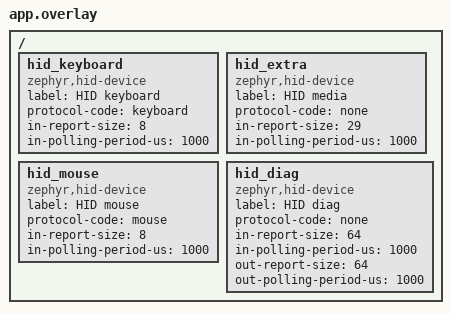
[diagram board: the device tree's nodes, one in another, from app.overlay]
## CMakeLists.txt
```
cmake_minimum_required(VERSION 3.20.0)

find_package(Zephyr REQUIRED HINTS $ENV{ZEPHYR_BASE})
project(spare_dongle)

set(manifest ${CMAKE_CURRENT_SOURCE_DIR}/tool/Cargo.toml)
set_property(DIRECTORY APPEND PROPERTY CMAKE_CONFIGURE_DEPENDS ${manifest})
file(STRINGS ${manifest} version_line REGEX "^version = \"[0-9]+\\.[0-9]+\\.[0-9]+\"$" LIMIT_COUNT 1)
if(NOT version_line MATCHES "([0-9]+)\\.([0-9]+)\\.([0-9]+)")
  message(FATAL_ERROR "no version line in ${manifest}")
endif()
set_property(SOURCE src/core.c APPEND PROPERTY COMPILE_DEFINITIONS
  FIRMWARE_VERSION_MAJOR=${CMAKE_MATCH_1} FIRMWARE_VERSION_MINOR=${CMAKE_MATCH_2}
  FIRMWARE_VERSION_PATCH=${CMAKE_MATCH_3})

target_sources(app PRIVATE
  src/main.c src/core.c src/nuphy_main.c src/unifying_main.c src/radio.c src/noise.c src/usb.c
  src/indicator.c src/nuphy.c src/unifying.c src/protocol.c src/reports.c src/chanpick.c
  src/link.c src/store.c src/diag.c src/history.c src/pairwin.c src/chanwatch.c
  src/ble.c src/bluetooth_main.c src/hidmap.c src/hidkeys.c src/hidpp.c
  src/btpolicy.c src/btlist.c src/bootinfo.c)

include(ffi/diagwire.cmake)
# CONFIG_FPU is off, so the firmware uses the soft-float ABI.
diagwire_build(thumbv7em-none-eabi)
target_link_libraries(app PRIVATE diagwire)
```

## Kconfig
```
mainmenu "spare-dongle"

config COUNTERS
	bool "Print link and USB counters on the console every 10 s"
	default y

source "Kconfig.zephyr"
```

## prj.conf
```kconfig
CONFIG_SERIAL=y
CONFIG_CONSOLE=y
CONFIG_UART_CONSOLE=y
CONFIG_UART_LINE_CTRL=y
CONFIG_PRINTK=y
CONFIG_USB_DEVICE_STACK_NEXT=y
CONFIG_CDC_ACM_SERIAL_INITIALIZE_AT_BOOT=n
CONFIG_USBD_CDC_ACM_CLASS=y
CONFIG_USBD_HID_SUPPORT=y
CONFIG_HWINFO=y
CONFIG_REBOOT=y
CONFIG_MAIN_STACK_SIZE=2048
CONFIG_ESB=y
CONFIG_CLOCK_CONTROL=y
CONFIG_ESB_CLOCK_INIT=y
CONFIG_FLASH=y
CONFIG_FLASH_MAP=y
CONFIG_NVS=y
CONFIG_SETTINGS=y
CONFIG_SETTINGS_NVS=y
CONFIG_WATCHDOG=y
CONFIG_ENTROPY_GENERATOR=y
CONFIG_ESB_DYNAMIC_INTERRUPTS=y
CONFIG_MPSL_DYNAMIC_INTERRUPTS=y
CONFIG_BT=y
CONFIG_BT_CENTRAL=y
CONFIG_BT_SMP=y
CONFIG_BT_SETTINGS=y
CONFIG_BT_GATT_CLIENT=y
CONFIG_BT_GATT_DM=y
CONFIG_BT_HOGP=y
CONFIG_BT_MAX_CONN=2
CONFIG_BT_MAX_PAIRED=8
CONFIG_BT_DEVICE_NAME="SpareDongle"
CONFIG_HEAP_MEM_POOL_SIZE=2048
CONFIG_SYSTEM_WORKQUEUE_STACK_SIZE=2048
CONFIG_BT_HOGP_REPORTS_MAX=16
CONFIG_BT_GATT_DM_MAX_ATTRS=80
CONFIG_BT_SMP_SC_PAIR_ONLY=n
CONFIG_BT_ATT_TX_COUNT=17
CONFIG_BT_BAS_CLIENT=y
CONFIG_BT_SCAN_WITH_IDENTITY=y
CONFIG_BT_APP_PASSKEY=y
CONFIG_BT_CTLR_CONN_RSSI=y
CONFIG_BT_HCI_VS_EVT_USER=y
CONFIG_BT_CTLR_SDC_QOS_CHANNEL_SURVEY=y
```

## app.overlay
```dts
/ {
	hid_keyboard: hid_keyboard {
		compatible = "zephyr,hid-device";
		label = "HID keyboard";
		protocol-code = "keyboard";
		in-report-size = <8>;
		in-polling-period-us = <1000>;
	};

	hid_extra: hid_extra {
		compatible = "zephyr,hid-device";
		label = "HID media";
		protocol-code = "none";
		in-report-size = <29>;
		in-polling-period-us = <1000>;
	};

	hid_mouse: hid_mouse {
		compatible = "zephyr,hid-device";
		label = "HID mouse";
		protocol-code = "mouse";
		in-report-size = <8>;
		in-polling-period-us = <1000>;
	};

	hid_diag: hid_diag {
		compatible = "zephyr,hid-device";
		label = "HID diag";
		protocol-code = "none";
		in-report-size = <64>;
		in-polling-period-us = <1000>;
		out-report-size = <64>;
		out-polling-period-us = <1000>;
	};
};
```

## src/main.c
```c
#include <hal/nrf_timer.h>
#include <zephyr/drivers/hwinfo.h>
#include <zephyr/init.h>
#include <zephyr/sys/printk.h>
#include "bootinfo.h"
#include "core.h"
#include "store.h"

/* The SoftDevice sits above the 4 kB MBR and keeps its information structure 0x2000 into itself. */
#define SD_INFO_ADDRESS 0x3000

static uint32_t bootloader_version_register;

/* TIMER2's CC[0] holds the bootloader's version only until a driver or radio stack reuses the
 * timer, and PRE_KERNEL_1 runs before any of them start. */
static int capture_bootloader_version(void)
{
	bootloader_version_register = nrf_timer_cc_get(NRF_TIMER2, NRF_TIMER_CC_CHANNEL0);
	return 0;
}

SYS_INIT(capture_bootloader_version, PRE_KERNEL_1, 0);

int main(void)
{
	uint32_t reset_cause = 0;
	uint8_t stored = 0;
	bool loaded = false;
	enum protocol active;
	struct bootinfo boot;
	int store_err;

	hwinfo_get_reset_cause(&reset_cause);
	hwinfo_clear_reset_cause();
	bootinfo_read(&boot, reset_cause, bootloader_version_register,
		      (const uint8_t *)SD_INFO_ADDRESS);
	store_err = store_init();
	if (store_err) {
		printk("store init failed: %d\n", store_err);
	} else {
		loaded = store_load_protocol(&stored);
	}
	active = protocol_from_stored(loaded, stored);
	core_start(active, &boot);
	if (active == PROTOCOL_BLUETOOTH) {
		bluetooth_run(store_err);
	}
	if (active == PROTOCOL_UNIFYING) {
		unifying_run(store_err);
	}
	nuphy_run(store_err);
	return 0;
}
```

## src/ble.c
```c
#include <string.h>
#include <zephyr/bluetooth/bluetooth.h>
#include <zephyr/bluetooth/conn.h>
#include <zephyr/bluetooth/gatt.h>
#include <zephyr/bluetooth/hci.h>
#include <zephyr/bluetooth/uuid.h>
#include <zephyr/kernel.h>
#include <zephyr/settings/settings.h>
#include <zephyr/sys/byteorder.h>
#include <zephyr/sys/printk.h>
#include <bluetooth/gatt_dm.h>
#include <bluetooth/hci_vs_sdc.h>
#include <bluetooth/services/bas_client.h>
#include <bluetooth/services/hogp.h>
/* Host-internal: the public API gives a bond's address but not how it paired. */
#include <host/keys.h>
#include "ble.h"
#include "clock.h"
#include "core.h"

K_MSGQ_DEFINE(ble_events, sizeof(struct ble_event), 16, 4);

BUILD_ASSERT(CONFIG_BT_MAX_CONN == DEVICE_KINDS);
BUILD_ASSERT(CONFIG_BT_MAX_PAIRED == BTPOLICY_STORED_MAX);
BUILD_ASSERT(BTPOLICY_APPEARANCE_KEYBOARD == BT_APPEARANCE_HID_KEYBOARD);
BUILD_ASSERT(BTPOLICY_APPEARANCE_MOUSE == BT_APPEARANCE_HID_MOUSE);

/* In the order waiting discoveries start. */
enum discovery {
	DISCOVERY_NONE,
	DISCOVERY_HID,
	DISCOVERY_BATTERY,
};

struct link {
	struct bt_conn *conn;
	struct bt_hogp hogp;
	struct bt_bas_client bas;
	uint8_t map[BLE_MAP_MAX];
	size_t map_len;
	char name[BLE_NAME_MAX + 1];
	struct bt_gatt_read_params name_read;
	enum discovery wanted;
	bool failed;
	bool passkey_used;
};

static struct link links[DEVICE_KINDS];
/* A new device's advert that lacked the HID service or a kind, kept for its scan response. */
static struct btpolicy_advert pending;
static bool pending_set;
static enum btpolicy_scan scan_mode;
static uint32_t passkey;
static bool offering;

static enum device_kind kind_of(const struct link *l)
{
	return (enum device_kind)(l - links);
}

static struct link *link_of_conn(const struct bt_conn *conn)
{
	for (int k = 0; k < DEVICE_KINDS; k++) {
		if (links[k].conn == conn) {
			return &links[k];
		}
	}
	return NULL;
}

static void put_event(const struct ble_event *ev)
{
	if (k_msgq_put(&ble_events, ev, K_NO_WAIT) != 0) {
		core_count_dropped();
		printk("bluetooth event dropped\n");
	}
}

static void emit(struct link *l, struct ble_event ev)
{
	ev.kind = kind_of(l);
	put_event(&ev);
}

static enum btpolicy_failure failure_of(enum ble_stage stage, int error)
{
	if (stage != BLE_STAGE_SECURITY || error == BT_SECURITY_ERR_UNSPECIFIED) {
		return BTPOLICY_FAILURE_LINK;
	}
	return error == BT_SECURITY_ERR_PIN_OR_KEY_MISSING ? BTPOLICY_FAILURE_KEY_MISSING
							   : BTPOLICY_FAILURE_REFUSAL;
}

static void emit_failed(struct link *l, enum ble_stage stage, int error)
{
	emit(l, (struct ble_event){
			.type = BLE_FAILED,
			.failed = {.stage = stage, .error = error, .why = failure_of(stage, error)},
		});
}

static void fail(struct link *l, enum ble_stage stage, int error)
{
	/* The stages still running when one fails, or when the connection is being closed, end in
	 * errors of their own. */
	if (l->failed) {
		return;
	}
	l->failed = true;
	emit_failed(l, stage, error);
	ble_disconnect(kind_of(l));
}

static void next_discovery(void);

static void want_discovery(struct link *l, enum discovery what)
{
	l->wanted = what;
	next_discovery();
}

static uint8_t on_report(struct bt_hogp *h, struct bt_hogp_rep_info *rep, uint8_t err,
			 const uint8_t *data)
{
	struct ble_event ev = {
		.type = BLE_REPORT,
		.report = {.received_us = clock_now_us(), .id = bt_hogp_rep_id(rep)},
	};
	size_t len = bt_hogp_rep_size(rep);

	if (err || !data) {
		return BT_GATT_ITER_STOP;
	}
	ev.report.len = MIN(len, sizeof(ev.report.data));
	memcpy(ev.report.data, data, ev.report.len);
	emit(CONTAINER_OF(h, struct link, hogp), ev);
	return BT_GATT_ITER_CONTINUE;
}

/* Each subscription holds an ATT buffer until the device answers, and all are sent at once, with
 * the battery discovery's first request behind them. */
BUILD_ASSERT(CONFIG_BT_ATT_TX_COUNT >= CONFIG_BT_HOGP_REPORTS_MAX + 1);

static void subscribe(struct link *l)
{
	struct bt_hogp_rep_info *rep = NULL;

	while ((rep = bt_hogp_rep_next(&l->hogp, rep)) != NULL) {
		int err;

		if (bt_hogp_rep_type(rep) != BT_HIDS_REPORT_TYPE_INPUT) {
			continue;
		}
		err = bt_hogp_rep_subscribe(&l->hogp, rep, on_report);
		if (err) {
			fail(l, BLE_STAGE_SUBSCRIBE, err);
			return;
		}
	}
	want_discovery(l, DISCOVERY_BATTERY);
}

static void on_map_part(struct bt_hogp *h, uint8_t err, const uint8_t *data, size_t size,
			size_t offset)
{
	struct link *l = CONTAINER_OF(h, struct link, hogp);
	int ret;

	if (err) {
		fail(l, BLE_STAGE_MAP, err);
		return;
	}
	if (!data || size == 0) {
		l->map_len = offset;
		emit(l, (struct ble_event){.type = BLE_MAP_READ});
		subscribe(l);
		return;
	}
	if (offset + size > sizeof(l->map)) {
		fail(l, BLE_STAGE_MAP, -ENOMEM);
		return;
	}
	memcpy(&l->map[offset], data, size);
	ret = bt_hogp_map_read(h, on_map_part, offset + size, K_NO_WAIT);
	if (ret) {
		fail(l, BLE_STAGE_MAP, ret);
	}
}

static void on_hogp_ready(struct bt_hogp *h)
{
	int err = bt_hogp_map_read(h, on_map_part, 0, K_NO_WAIT);

	if (err) {
		fail(CONTAINER_OF(h, struct link, hogp), BLE_STAGE_MAP, err);
	}
}

static void on_hogp_failed(struct bt_hogp *h, int err)
{
	fail(CONTAINER_OF(h, struct link, hogp), BLE_STAGE_HID_SETUP, err);
}

static const struct bt_hogp_init_params hogp_params = {
	.ready_cb = on_hogp_ready,
	.prep_error_cb = on_hogp_failed,
};

/* bt_gatt_dm can end a discovery after its connection closed. */
static struct link *discovering;

/* Must run before next_discovery, which overwrites discovering. */
static struct link *take_discovering(void)
{
	struct link *l = discovering;

	discovering = NULL;
	return l;
}

static void on_discovered(struct bt_gatt_dm *dm, void *context)
{
	struct link *l = take_discovering();
	int err;

	ARG_UNUSED(context);
	if (!l) {
		bt_gatt_dm_data_release(dm);
		next_discovery();
		return;
	}
	err = bt_hogp_handles_assign(dm, &l->hogp);
	bt_gatt_dm_data_release(dm);
	next_discovery();
	if (err) {
		fail(l, BLE_STAGE_HID_SETUP, err);
	}
}

static void on_discovery_error(struct bt_conn *conn, int err, void *context)
{
	struct link *l = take_discovering();

	ARG_UNUSED(conn);
	ARG_UNUSED(context);
	next_discovery();
	if (l) {
		fail(l, BLE_STAGE_DISCOVERY, err);
	}
}

static void on_no_hid_service(struct bt_conn *conn, void *context)
{
	on_discovery_error(conn, -ENOENT, context);
}

static const struct bt_gatt_dm_cb hid_discovery = {
	.completed = on_discovered,
	.service_not_found = on_no_hid_service,
	.error_found = on_discovery_error,
};

static void emit_battery(struct bt_bas_client *bas, uint8_t level)
{
	struct device_battery b = DEVICE_BATTERY_UNKNOWN;

	if (level != BT_BAS_VAL_INVALID) {
		b.level = level;
	}
	emit(CONTAINER_OF(bas, struct link, bas),
	     (struct ble_event){.type = BLE_BATTERY, .battery = b});
}

static void on_battery_read(struct bt_bas_client *bas, uint8_t level, int err)
{
	emit_battery(bas, err ? BT_BAS_VAL_INVALID : level);
}

static void use_battery(struct link *l, struct bt_gatt_dm *dm)
{
	int err = bt_bas_handles_assign(dm, &l->bas);

	if (!err) {
		err = bt_bas_read_battery_level(&l->bas, on_battery_read);
	}
	if (!err && bt_bas_notify_supported(&l->bas)) {
		err = bt_bas_subscribe_battery_level(&l->bas, emit_battery);
	}
	if (err) {
		printk("bluetooth %s battery unread: %d\n", device_kind_name(kind_of(l)), err);
	}
}

static void on_battery_found(struct bt_gatt_dm *dm, void *context)
{
	struct link *l = take_discovering();

	ARG_UNUSED(context);
	if (l) {
		use_battery(l, dm);
	}
	bt_gatt_dm_data_release(dm);
	next_discovery();
}

static void on_no_battery(struct bt_conn *conn, void *context)
{
	ARG_UNUSED(conn);
	ARG_UNUSED(context);
	take_discovering();
	next_discovery();
}

static void on_battery_error(struct bt_conn *conn, int err, void *context)
{
	struct link *l = take_discovering();

	ARG_UNUSED(conn);
	ARG_UNUSED(context);
	if (l) {
		printk("bluetooth %s battery discovery failed: %d\n",
		       device_kind_name(kind_of(l)), err);
	}
	next_discovery();
}

static const struct bt_gatt_dm_cb battery_discovery = {
	.completed = on_battery_found,
	.service_not_found = on_no_battery,
	.error_found = on_battery_error,
};

static int start_discovery(struct link *l, enum discovery what)
{
	int err = what == DISCOVERY_HID
			  ? bt_gatt_dm_start(l->conn, BT_UUID_HIDS, &hid_discovery, NULL)
			  : bt_gatt_dm_start(l->conn, BT_UUID_BAS, &battery_discovery, NULL);

	if (!err) {
		discovering = l;
	}
	return err;
}

/* bt_gatt_dm runs one discovery at a time and refuses a second start with -EALREADY. */
static void next_discovery(void)
{
	for (;;) {
		struct link *l = NULL;
		enum discovery what;
		int err;

		for (int k = 0; k < DEVICE_KINDS; k++) {
			if (links[k].wanted != DISCOVERY_NONE &&
			    (!l || links[k].wanted < l->wanted)) {
				l = &links[k];
			}
		}
		if (!l) {
			return;
		}
		what = l->wanted;
		err = start_discovery(l, what);
		if (err == -EALREADY) {
			return;
		}
		l->wanted = DISCOVERY_NONE;
		if (!err) {
			return;
		}
		if (what == DISCOVERY_HID) {
			fail(l, BLE_STAGE_DISCOVERY, err);
		} else {
			printk("bluetooth %s battery discovery not started: %d\n",
			       device_kind_name(kind_of(l)), err);
		}
	}
}

static void copy_name(char out[BLE_NAME_MAX + 1], const void *data, size_t len)
{
	len = MIN(len, BLE_NAME_MAX);
	memcpy(out, data, len);
	out[len] = '\0';
}

static uint8_t on_name(struct bt_conn *conn, uint8_t err, struct bt_gatt_read_params *params,
		       const void *data, uint16_t length)
{
	struct link *l = CONTAINER_OF(params, struct link, name_read);

	ARG_UNUSED(conn);
	if (!err && data) {
		copy_name(l->name, data, length);
	}
	want_discovery(l, DISCOVERY_HID);
	return BT_GATT_ITER_STOP;
}

static void read_name(struct link *l)
{
	l->name_read = (struct bt_gatt_read_params){
		.func = on_name,
		.by_uuid = {
			.start_handle = BT_ATT_FIRST_ATTRIBUTE_HANDLE,
			.end_handle = BT_ATT_LAST_ATTRIBUTE_HANDLE,
			.uuid = BT_UUID_GAP_DEVICE_NAME,
		},
	};
	if (bt_gatt_read(l->conn, &l->name_read) != 0) {
		want_discovery(l, DISCOVERY_HID);
	}
}

BUILD_ASSERT(BLE_ADDRESS_MAX >= BT_ADDR_LE_STR_LEN);
BUILD_ASSERT(BLE_REASON_NOT_ESTABLISHED == BT_HCI_ERR_CONN_FAIL_TO_ESTAB);
BUILD_ASSERT(sizeof(bt_addr_le_t) == BTPOLICY_ADDR_LEN);

static void connection_ended(struct link *l, uint8_t reason)
{
	if (bt_hogp_assign_check(&l->hogp)) {
		bt_hogp_release(&l->hogp);
	}
	l->wanted = DISCOVERY_NONE;
	if (discovering == l) {
		discovering = NULL;
	}
	bt_conn_unref(l->conn);
	l->conn = NULL;
	emit(l, (struct ble_event){.type = BLE_DISCONNECTED, .reason = reason});
}

static void print_params(struct link *l)
{
	struct bt_conn_info info;

	if (bt_conn_get_info(l->conn, &info) == 0) {
		printk("bluetooth %s link: interval %u us, latency %u, timeout %u ms\n",
		       device_kind_name(kind_of(l)), info.le.interval_us,
		       info.le.latency, info.le.timeout * 10u);
	}
}

static void on_connected(struct bt_conn *conn, uint8_t err)
{
	struct link *l = link_of_conn(conn);
	struct ble_event ev = {.type = BLE_CONNECTED};
	int ret;

	if (!l) {
		return;
	}
	if (err) {
		emit_failed(l, BLE_STAGE_CONNECT, err);
		connection_ended(l, err);
		return;
	}
	l->map_len = 0;
	bt_addr_le_to_str(bt_conn_get_dst(conn), ev.address, sizeof(ev.address));
	emit(l, ev);
	print_params(l);
	l->passkey_used = false;
	l->failed = false;
	ret = bt_conn_set_security(conn, BT_SECURITY_L2);
	if (ret) {
		fail(l, BLE_STAGE_SECURITY, ret);
	}
}

static void on_disconnected(struct bt_conn *conn, uint8_t reason)
{
	struct link *l = link_of_conn(conn);

	if (l) {
		connection_ended(l, reason);
	}
}

static void on_security_changed(struct bt_conn *conn, bt_security_t level,
				enum bt_security_err err)
{
	struct link *l = link_of_conn(conn);

	ARG_UNUSED(level);
	if (!l) {
		return;
	}
	if (err) {
		fail(l, BLE_STAGE_SECURITY, err);
		return;
	}
	read_name(l);
}

static void on_params_updated(struct bt_conn *conn, uint16_t interval, uint16_t latency,
			      uint16_t timeout)
{
	struct link *l = link_of_conn(conn);

	ARG_UNUSED(interval);
	ARG_UNUSED(latency);
	ARG_UNUSED(timeout);
	if (l) {
		print_params(l);
	}
}

BT_CONN_CB_DEFINE(conn_callbacks) = {
	.connected = on_connected,
	.disconnected = on_disconnected,
	.security_changed = on_security_changed,
	.le_param_updated = on_params_updated,
};

static void on_pairing_complete(struct bt_conn *conn, bool bonded)
{
	struct link *l = link_of_conn(conn);

	if (l && bonded) {
		emit(l, (struct ble_event){.type = BLE_PAIRED, .passkey_used = l->passkey_used});
	}
}

static struct bt_conn_auth_info_cb pairing_callbacks = {
	.pairing_complete = on_pairing_complete,
};

static bool parse_field(struct bt_data *data, void *user_data)
{
	struct btpolicy_advert *a = user_data;

	if (data->type == BT_DATA_NAME_COMPLETE || data->type == BT_DATA_NAME_SHORTENED) {
		copy_name(a->name, data->data, data->data_len);
	}

	if (data->type == BT_DATA_GAP_APPEARANCE && data->data_len == 2 &&
	    a->kind == DEVICE_NO_KIND) {
		a->kind = btpolicy_kind_of(sys_get_le16(data->data));
	}
	if (data->type != BT_DATA_UUID16_SOME && data->type != BT_DATA_UUID16_ALL) {
		return true;
	}
	for (size_t i = 0; i + 1 < data->data_len; i += 2) {
		if (sys_get_le16(&data->data[i]) == BT_UUID_HIDS_VAL) {
			a->hid_service = true;
		}
	}
	return true;
}

static void on_advert(const bt_addr_le_t *addr, int8_t rssi, uint8_t type,
		      struct net_buf_simple *data)
{
	struct ble_event ev = {.type = BLE_ADVERT};
	struct btpolicy_advert *a = &ev.advert;
	bool response = type == BT_GAP_ADV_TYPE_SCAN_RSP;

	ARG_UNUSED(rssi);
	if (response) {
		if (!pending_set || memcmp(pending.addr, addr, sizeof(pending.addr)) != 0) {
			return;
		}
		*a = pending;
		pending_set = false;
	} else {
		a->directed = type == BT_GAP_ADV_TYPE_ADV_DIRECT_IND;
		a->connectable = a->directed || type == BT_GAP_ADV_TYPE_ADV_IND;
		a->stored = bt_le_bond_exists(BT_ID_DEFAULT, addr);
		a->kind = DEVICE_NO_KIND;
		memcpy(a->addr, addr, sizeof(a->addr));
	}
	if (!a->directed) {
		bt_data_parse(data, parse_field, a);
	}
	/* Adverts from other devices would fill the event queue. */
	if (!btpolicy_interesting(a)) {
		if (!response && scan_mode == BTPOLICY_SCAN_ACTIVE && a->connectable &&
		    !a->directed) {
			pending = *a;
			pending_set = true;
		}
		return;
	}
	put_event(&ev);
}

int ble_scan(enum btpolicy_scan mode)
{
	bool pairing;
	int err;

	if (mode == scan_mode) {
		return 0;
	}
	if (scan_mode != BTPOLICY_SCAN_OFF) {
		err = bt_le_scan_stop();
		if (err) {
			return err;
		}
		scan_mode = BTPOLICY_SCAN_OFF;
	}
	if (mode == BTPOLICY_SCAN_OFF) {
		return 0;
	}
	pending_set = false;
	pairing = mode == BTPOLICY_SCAN_ACTIVE;
	/* The fast scan window takes radio time from a connected mouse, about an eighth of its
	 * reports. */
	err = bt_le_scan_start(
		BT_LE_SCAN_PARAM(pairing ? BT_LE_SCAN_TYPE_ACTIVE : BT_LE_SCAN_TYPE_PASSIVE,
				 BT_LE_SCAN_OPT_NONE,
				 pairing ? BT_GAP_SCAN_FAST_INTERVAL : BT_GAP_SCAN_SLOW_INTERVAL_1,
				 pairing ? BT_GAP_SCAN_FAST_WINDOW : BT_GAP_SCAN_SLOW_WINDOW_1),
		on_advert);
	if (!err) {
		scan_mode = mode;
	}
	return err;
}

/* Reading a device's services takes dozens of exchanges, each two connection intervals long. */
#define SHORTEST_INTERVAL 6 /* 7.5 ms */
#define SETUP_CONN_PARAM                                                                           \
	BT_LE_CONN_PARAM(SHORTEST_INTERVAL, SHORTEST_INTERVAL, 0, BT_GAP_MS_TO_CONN_TIMEOUT(4000))

int ble_connect(enum device_kind kind, const uint8_t addr[BTPOLICY_ADDR_LEN],
		const char *advertised_name)
{
	struct link *l = &links[kind];
	bt_addr_le_t peer;
	int err;

	if (l->conn) {
		return -EALREADY;
	}
	copy_name(l->name, advertised_name, strlen(advertised_name));
	memcpy(&peer, addr, sizeof(peer));
	err = bt_conn_le_create(&peer, BT_CONN_LE_CREATE_CONN, SETUP_CONN_PARAM, &l->conn);
	if (err) {
		l->conn = NULL;
	}
	return err;
}

/* Each passkey serves one pairing, since a failed or abandoned attempt can reveal it. */
static uint32_t on_app_passkey(struct bt_conn *conn)
{
	struct link *l = link_of_conn(conn);
	uint32_t offered = passkey;

	if (l) {
		l->passkey_used = true;
		emit(l, (struct ble_event){.type = BLE_PASSKEY_AWAITED, .passkey = offered});
	}
	passkey = BT_PASSKEY_RAND;
	return offered;
}

static void on_pairing_cancel(struct bt_conn *conn)
{
	ARG_UNUSED(conn);
}

static const struct bt_conn_auth_cb passkey_callbacks = {
	.app_passkey = on_app_passkey,
	.cancel = on_pairing_cancel,
};

int ble_offer_passkey(bool on, uint32_t value)
{
	int err;

	passkey = value;
	if (on == offering) {
		return 0;
	}
	err = bt_conn_auth_cb_register(on ? &passkey_callbacks : NULL);
	if (!err) {
		offering = on;
	}
	return err;
}

struct bonds {
	uint8_t (*addrs)[BTPOLICY_ADDR_LEN];
	uint8_t cap;
	uint8_t count;
};

static void add_bond(const struct bt_bond_info *info, void *user_data)
{
	struct bonds *bonds = user_data;

	if (bonds->count < bonds->cap) {
		memcpy(bonds->addrs[bonds->count], &info->addr, BTPOLICY_ADDR_LEN);
	}
	bonds->count++;
}

uint8_t ble_stored(uint8_t addrs[][BTPOLICY_ADDR_LEN], uint8_t cap)
{
	struct bonds bonds = {.addrs = addrs, .cap = cap};

	bt_foreach_bond(BT_ID_DEFAULT, add_bond, &bonds);
	return bonds.count;
}

uint8_t ble_stored_count(void)
{
	return ble_stored(NULL, 0);
}

int ble_forget(const uint8_t addr[BTPOLICY_ADDR_LEN])
{
	bt_addr_le_t peer;

	memcpy(&peer, addr, sizeof(peer));
	return bt_unpair(BT_ID_DEFAULT, &peer);
}

/* The advertising channels hold the indexes above these, and nearby devices advertise there all the
 * time. */
#define DATA_CHANNELS 37
#define ENERGY_NOT_MEASURED 127
#define SURVEY_INTERVAL_US 10000

/* The host's receive thread adds to the tally while the main loop takes it. */
static struct noise_tally data_noise;

static bool on_vendor_event(struct net_buf_simple *buf)
{
	const sdc_hci_subevent_vs_qos_channel_survey_report_t *r;

	if (net_buf_simple_pull_u8(buf) != SDC_HCI_SUBEVENT_VS_QOS_CHANNEL_SURVEY_REPORT ||
	    buf->len < sizeof(*r)) {
		return false;
	}
	r = (const void *)buf->data;
	k_sched_lock();
	for (int ch = 0; ch < DATA_CHANNELS; ch++) {
		if (r->channel_energy[ch] != ENERGY_NOT_MEASURED) {
			noise_add(&data_noise, r->channel_energy[ch]);
		}
	}
	k_sched_unlock();
	return true;
}

static int start_survey(void)
{
	sdc_hci_cmd_vs_qos_channel_survey_enable_t survey = {
		.enable = 1,
		.interval_us = SURVEY_INTERVAL_US,
	};
	int err = bt_hci_register_vnd_evt_cb(on_vendor_event);

	return err ? err : hci_vs_sdc_qos_channel_survey_enable(&survey);
}

bool ble_take_noise(struct noise_tally *t, int *home)
{
	k_sched_lock();
	*t = data_noise;
	data_noise = (struct noise_tally){0};
	k_sched_unlock();
	*home = CHANMOVE_NO_HOME;
	return true;
}

int ble_start(void)
{
	int err = bt_enable(NULL);

	if (!err) {
		err = settings_load();
	}
	if (!err) {
		err = bt_conn_auth_info_cb_register(&pairing_callbacks);
	}
	for (int k = 0; !err && k < DEVICE_KINDS; k++) {
		bt_hogp_init(&links[k].hogp, &hogp_params);
		bt_bas_client_init(&links[k].bas);
	}
	if (!err) {
		int survey_err = start_survey();

		if (survey_err) {
			printk("bluetooth noise survey not started: %d\n", survey_err);
		}
	}
	return err;
}

bool ble_take_event(struct ble_event *ev, k_timeout_t wait)
{
	return k_msgq_get(&ble_events, ev, wait) == 0;
}

size_t ble_copy_map(enum device_kind kind, uint8_t *out, size_t cap)
{
	size_t len;

	k_sched_lock();
	len = MIN(links[kind].map_len, cap);
	memcpy(out, links[kind].map, len);
	k_sched_unlock();
	return len;
}

void ble_copy_name(enum device_kind kind, char out[BLE_NAME_MAX + 1])
{
	k_sched_lock();
	memcpy(out, links[kind].name, sizeof(links[kind].name));
	k_sched_unlock();
}

void ble_disconnect(enum device_kind kind)
{
	struct link *l = &links[kind];

	l->failed = true;
	if (l->conn) {
		bt_conn_disconnect(l->conn, BT_HCI_ERR_REMOTE_USER_TERM_CONN);
	}
}

static void on_written(struct bt_hogp *h, struct bt_hogp_rep_info *rep, uint8_t err)
{
	ARG_UNUSED(h);
	ARG_UNUSED(rep);
	ARG_UNUSED(err);
}

int ble_write_report(enum device_kind kind, uint8_t report_id, const uint8_t *data, uint8_t len)
{
	struct bt_hogp *hogp = &links[kind].hogp;
	struct bt_hogp_rep_info *rep;

	if (!bt_hogp_ready_check(hogp)) {
		return -ENOTCONN;
	}
	rep = bt_hogp_rep_find(hogp, BT_HIDS_REPORT_TYPE_OUTPUT, report_id);
	if (!rep) {
		return -ENOENT;
	}
	/* The library refuses a write without a completion callback. */
	return bt_hogp_rep_write_wo_rsp(hogp, rep, data, len, on_written);
}

bool ble_bond_secure(const uint8_t addr[BTPOLICY_ADDR_LEN])
{
	bt_addr_le_t peer;
	const struct bt_keys *keys;

	memcpy(&peer, addr, sizeof(peer));
	keys = bt_keys_find_addr(BT_ID_DEFAULT, &peer);
	return keys && (keys->flags & BT_KEYS_SC);
}

int ble_rssi(enum device_kind kind, int8_t *dbm)
{
	struct bt_conn *conn = links[kind].conn;
	struct bt_hci_cp_read_rssi *cp;
	struct net_buf *buf;
	struct net_buf *rsp;
	uint16_t handle;
	int8_t rssi;
	int err;

	if (!conn || bt_hci_get_conn_handle(conn, &handle)) {
		return -ENOTCONN;
	}
	buf = bt_hci_cmd_alloc(K_MSEC(10));
	if (!buf) {
		return -ENOBUFS;
	}
	cp = net_buf_add(buf, sizeof(*cp));
	cp->handle = sys_cpu_to_le16(handle);
	err = bt_hci_cmd_send_sync(BT_HCI_OP_READ_RSSI, buf, &rsp);
	if (err) {
		return err;
	}
	rssi = ((struct bt_hci_rp_read_rssi *)rsp->data)->rssi;
	net_buf_unref(rsp);
	if (rssi == BT_HCI_LE_RSSI_NOT_AVAILABLE) {
		return -ENODATA;
	}
	*dbm = rssi;
	return 0;
}

const char *ble_stage_name(enum ble_stage stage)
{
	switch (stage) {
	case BLE_STAGE_CONNECT:
		return "connect";
	case BLE_STAGE_SECURITY:
		return "security";
	case BLE_STAGE_DISCOVERY:
		return "discovery";
	case BLE_STAGE_HID_SETUP:
		return "hid setup";
	case BLE_STAGE_MAP:
		return "report map";
	case BLE_STAGE_SUBSCRIBE:
		return "subscribe";
	}
	return "unknown";
}
```

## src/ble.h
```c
#ifndef BLE_H
#define BLE_H

#include <stdbool.h>
#include <stddef.h>
#include <stdint.h>

#include <zephyr/kernel.h>

#include "btpolicy.h"
#include "noise.h"

#define BLE_REPORT_MAX 64
#define BLE_MAP_MAX 1024
#define BLE_NAME_MAX BTPOLICY_NAME_MAX
#define BLE_ADDRESS_MAX 30
#define BLE_REASON_NOT_ESTABLISHED 0x3e

enum ble_event_type {
	BLE_ADVERT,
	BLE_CONNECTED,
	BLE_DISCONNECTED,
	BLE_FAILED,
	BLE_PAIRED,
	/* The device waits for the offered passkey to be typed on it. */
	BLE_PASSKEY_AWAITED,
	BLE_MAP_READ,
	BLE_REPORT,
	BLE_BATTERY,
};

enum ble_stage {
	BLE_STAGE_CONNECT,
	BLE_STAGE_SECURITY,
	BLE_STAGE_DISCOVERY,
	BLE_STAGE_HID_SETUP,
	BLE_STAGE_MAP,
	BLE_STAGE_SUBSCRIBE,
};

struct ble_event {
	enum ble_event_type type;
	/* The slot the event is about; unset for BLE_ADVERT. */
	enum device_kind kind;
	union {
		/* BLE_ADVERT: from a stored device or one offering the HID service. */
		struct btpolicy_advert advert;
		/* BLE_CONNECTED: the device's address as text. */
		char address[BLE_ADDRESS_MAX];
		/* BLE_DISCONNECTED: the stack's reason code, BLE_REASON_NOT_ESTABLISHED when the
		 * device never joined the connection. */
		uint8_t reason;
		/* BLE_FAILED */
		struct {
			enum ble_stage stage;
			int error;
			enum btpolicy_failure why;
		} failed;
		/* BLE_PAIRED: the device was typed the offered passkey. */
		bool passkey_used;
		/* BLE_PASSKEY_AWAITED: the passkey the device was given. */
		uint32_t passkey;
		/* BLE_REPORT: the bytes exclude the report ID. */
		struct {
			uint32_t received_us;
			uint8_t id;
			uint8_t len;
			uint8_t data[BLE_REPORT_MAX];
		} report;
		/* BLE_BATTERY: the level is unknown once it cannot be read. */
		struct device_battery battery;
	};
};

/* Starts the Bluetooth stack; a second call fails with -EALREADY once the first has run. */
int ble_start(void);
/* Does nothing when scanning is already in the mode asked for; an active scan asks every
 * advertiser for its scan response. */
int ble_scan(enum btpolicy_scan mode);
/* Every call that returns 0 ends in one BLE_DISCONNECTED for the slot, after a BLE_FAILED when a
 * stage failed. */
int ble_connect(enum device_kind kind, const uint8_t addr[BTPOLICY_ADDR_LEN],
		const char *advertised_name);
/* While on, a keyboard able to take a passkey is asked for this six-digit one as it pairs. */
int ble_offer_passkey(bool on, uint32_t value);
uint8_t ble_stored_count(void);
/* Copies up to cap bonded addresses and returns how many bonds there are. */
uint8_t ble_stored(uint8_t addrs[][BTPOLICY_ADDR_LEN], uint8_t cap);
/* Deletes the device's bond, disconnecting it first if it is connected. */
int ble_forget(const uint8_t addr[BTPOLICY_ADDR_LEN]);
bool ble_take_event(struct ble_event *ev, k_timeout_t wait);
/* Copies the report map read at the slot's connection and returns its length, 0 before its
 * BLE_MAP_READ. */
size_t ble_copy_map(enum device_kind kind, uint8_t *out, size_t cap);
/* The name of the slot's device, the advertised one until its own is read; empty if it gave
 * none. */
void ble_copy_name(enum device_kind kind, char out[BLE_NAME_MAX + 1]);
void ble_disconnect(enum device_kind kind);
/* Writes the slot's output report with this ID, data excluding the ID; fails until the device's
 * reports are discovered and while an earlier write to that report is still being sent. */
int ble_write_report(enum device_kind kind, uint8_t report_id, const uint8_t *data, uint8_t len);
/* Reads the slot's signal from the controller; fails with -ENOTCONN without a device and -ENODATA
 * when the controller has no reading yet. */
int ble_rssi(enum device_kind kind, int8_t *dbm);
/* Whether the bond with the device was made by LE Secure Connections, not legacy pairing; false
 * for an address without a bond. */
bool ble_bond_secure(const uint8_t addr[BTPOLICY_ADDR_LEN]);
const char *ble_stage_name(enum ble_stage stage);
/* Takes the energy read on the data channels since the last call; it always counts toward the
 * minute, since the links hop over every data channel; *home is always CHANMOVE_NO_HOME. */
bool ble_take_noise(struct noise_tally *t, int *home);

#endif
```

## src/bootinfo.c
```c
#include <string.h>
#include "bootinfo.h"

#define SD_INFO_SIZE 0x00
#define SD_MAGIC 0x04
#define SD_FWID 0x0c
#define SD_ID 0x10
#define SD_VERSION 0x14
#define SD_MAGIC_NUMBER 0x51b1e5dbu

static uint32_t le32(const uint8_t *p)
{
	return p[0] | p[1] << 8 | p[2] << 16 | (uint32_t)p[3] << 24;
}

void bootinfo_read(struct bootinfo *out, uint32_t reset_cause, uint32_t version_register,
		   const uint8_t sd_info[BOOTINFO_SD_INFO_LEN])
{
	memset(out, 0, sizeof(*out));
	out->reset_cause = reset_cause;
	/* The bootloader packs major, minor and patch into the low three bytes. */
	if ((version_register >> 24) == 0) {
		out->bootloader[0] = version_register >> 16;
		out->bootloader[1] = version_register >> 8;
		out->bootloader[2] = version_register;
	}
	if (le32(&sd_info[SD_MAGIC]) != SD_MAGIC_NUMBER) {
		return;
	}
	out->softdevice_fwid = sd_info[SD_FWID] | sd_info[SD_FWID + 1] << 8;
	/* A field lies inside the structure only where its size byte reaches past the field's
	 * offset. */
	if (sd_info[SD_INFO_SIZE] > SD_ID) {
		out->softdevice_id = le32(&sd_info[SD_ID]);
	}
	if (sd_info[SD_INFO_SIZE] > SD_VERSION) {
		out->softdevice_version = le32(&sd_info[SD_VERSION]);
	}
}
```

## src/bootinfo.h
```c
#ifndef BOOTINFO_H
#define BOOTINFO_H

#include <stdint.h>

#include "diagwire.h"

/* The SoftDevice information structure's fields up to and including its version. */
#define BOOTINFO_SD_INFO_LEN 0x18

/* version_register is TIMER2's CC[0] as the Adafruit bootloader leaves it; sd_info is the flash at
 * the SoftDevice's information structure. */
void bootinfo_read(struct bootinfo *out, uint32_t reset_cause, uint32_t version_register,
		   const uint8_t sd_info[BOOTINFO_SD_INFO_LEN]);

#endif
```

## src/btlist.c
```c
#include <string.h>

#include "btlist.h"

#define NOT_LISTED UINT8_MAX

static uint8_t find(const struct btlist *l, const uint8_t *addr)
{
	for (uint8_t i = 0; i < l->count; i++) {
		if (memcmp(l->entries[i].addr, addr, BTPOLICY_ADDR_LEN) == 0) {
			return i;
		}
	}
	return NOT_LISTED;
}

static void remove_at(struct btlist *l, uint8_t at)
{
	memmove(&l->entries[at], &l->entries[at + 1],
		(l->count - at - 1) * sizeof(l->entries[0]));
	l->count--;
}

/* Puts the device's entry first, creating it if there is room; NULL when there is not. */
static struct btlist_entry *to_front(struct btlist *l, const uint8_t *addr, bool *changed)
{
	struct btlist_entry e = {0};
	uint8_t at = find(l, addr);

	if (at == NOT_LISTED) {
		if (l->count == BTPOLICY_STORED_MAX) {
			return NULL;
		}
		memcpy(e.addr, addr, BTPOLICY_ADDR_LEN);
		at = l->count++;
		*changed = true;
	} else {
		e = l->entries[at];
		*changed = at != 0;
	}
	memmove(&l->entries[1], &l->entries[0], at * sizeof(l->entries[0]));
	l->entries[0] = e;
	return &l->entries[0];
}

bool btlist_reconcile(struct btlist *l, const uint8_t addrs[][BTPOLICY_ADDR_LEN], size_t n)
{
	bool changed = false;

	for (uint8_t i = l->count; i-- > 0;) {
		bool bonded = false;

		for (size_t j = 0; j < n; j++) {
			bonded |= memcmp(l->entries[i].addr, addrs[j], BTPOLICY_ADDR_LEN) == 0;
		}
		if (!bonded) {
			remove_at(l, i);
			changed = true;
		}
	}
	for (size_t j = 0; j < n && l->count < BTPOLICY_STORED_MAX; j++) {
		if (find(l, addrs[j]) == NOT_LISTED) {
			l->entries[l->count] = (struct btlist_entry){0};
			memcpy(l->entries[l->count++].addr, addrs[j], BTPOLICY_ADDR_LEN);
			changed = true;
		}
	}
	return changed;
}

static bool set_name(struct btlist_entry *e, const char *name)
{
	char padded[BTLIST_NAME_LEN] = {0};

	strncpy(padded, name, sizeof(padded));
	if (memcmp(e->name, padded, sizeof(padded)) == 0) {
		return false;
	}
	memcpy(e->name, padded, sizeof(padded));
	return true;
}

bool btlist_connected(struct btlist *l, const uint8_t *addr, const char *name)
{
	bool changed = false;
	struct btlist_entry *e = to_front(l, addr, &changed);

	if (!e) {
		return false;
	}
	return set_name(e, name) || changed;
}

bool btlist_paired(struct btlist *l, const uint8_t *addr, enum device_kind kind,
		   bool no_passkey, const char *name)
{
	bool changed = false;
	struct btlist_entry *e = to_front(l, addr, &changed);

	if (!e) {
		return false;
	}
	if (e->no_passkey != no_passkey || e->kind != kind) {
		e->no_passkey = no_passkey;
		e->kind = kind;
		changed = true;
	}
	if (name[0] != '\0' && set_name(e, name)) {
		changed = true;
	}
	return changed;
}

bool btlist_remove(struct btlist *l, const uint8_t *addr)
{
	uint8_t at = find(l, addr);

	if (at == NOT_LISTED) {
		return false;
	}
	remove_at(l, at);
	return true;
}

const struct btlist_entry *btlist_entry(const struct btlist *l, const uint8_t *addr)
{
	uint8_t at = find(l, addr);

	return at == NOT_LISTED ? NULL : &l->entries[at];
}

bool btlist_has(const struct btlist *l, const uint8_t *addr)
{
	return btlist_entry(l, addr) != NULL;
}

bool btlist_has_kind(const struct btlist *l, enum device_kind kind)
{
	return btlist_latest(l, kind) != NULL;
}

const struct btlist_entry *btlist_latest(const struct btlist *l, enum device_kind kind)
{
	for (uint8_t i = 0; i < l->count; i++) {
		if (l->entries[i].kind == kind) {
			return &l->entries[i];
		}
	}
	return NULL;
}

enum device_kind btlist_kind(const struct btlist *l, const uint8_t *addr)
{
	const struct btlist_entry *e = btlist_entry(l, addr);

	return e ? e->kind : DEVICE_NO_KIND;
}

_Static_assert(BTPOLICY_ADDR_LEN == DIAG_ADDR_LEN, "a device list carries the whole address");
_Static_assert(BTPOLICY_STORED_MAX <= DIAG_STORED_MAX, "a device list carries every device");

uint8_t btlist_pairing(const struct btlist_entry *e, bool secure)
{
	return diag_pairing(secure, !e->no_passkey);
}

size_t btlist_devices(const struct btlist *l, const uint8_t *const connected[DEVICE_SLOTS],
		      bool (*secure)(const uint8_t addr[BTPOLICY_ADDR_LEN]),
		      struct diag_device out[BTPOLICY_STORED_MAX])
{
	for (uint8_t i = 0; i < l->count; i++) {
		const struct btlist_entry *e = &l->entries[i];

		out[i] = (struct diag_device){
			.kind = e->kind,
			.pairing = btlist_pairing(e, secure(e->addr)),
			.slot = DEVICE_NO_SLOT,
		};
		memcpy(out[i].addr, e->addr, sizeof(out[i].addr));
		memcpy(out[i].name, e->name, sizeof(out[i].name));
		for (uint8_t s = 0; s < DEVICE_SLOTS; s++) {
			if (connected[s] && memcmp(e->addr, connected[s], BTPOLICY_ADDR_LEN) == 0) {
				out[i].slot = s;
			}
		}
	}
	return l->count;
}
```

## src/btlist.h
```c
#ifndef BTLIST_H
#define BTLIST_H

#include <stdbool.h>
#include <stddef.h>
#include <stdint.h>

#include "btpolicy.h"
#include "device.h"

#define BTLIST_NAME_LEN DIAG_NAME_MAX

struct btlist_entry {
	uint8_t addr[BTPOLICY_ADDR_LEN];
	/* Padded with zeros; not terminated when it fills the field. */
	char name[BTLIST_NAME_LEN];
	bool no_passkey;
	/* An enum device_kind; zero, a keyboard, for an entry added by btlist_reconcile. */
	uint8_t kind;
};

/* The stored devices, the most recently connected first. */
struct btlist {
	struct btlist_entry entries[BTPOLICY_STORED_MAX];
	uint8_t count;
};

/* Each of these returns true when it changed the list. */

/* Drops the entries no bond backs and adds a nameless entry, last, for each bond without one. */
bool btlist_reconcile(struct btlist *l, const uint8_t addrs[][BTPOLICY_ADDR_LEN], size_t n);
/* Moves the device to the front and records its name. */
bool btlist_connected(struct btlist *l, const uint8_t *addr, const char *name);
/* Moves the device to the front and records its kind, its passkey mark and, unless empty, its
 * name. */
bool btlist_paired(struct btlist *l, const uint8_t *addr, enum device_kind kind,
		   bool no_passkey, const char *name);
bool btlist_remove(struct btlist *l, const uint8_t *addr);

/* NULL for an address not in the list. */
const struct btlist_entry *btlist_entry(const struct btlist *l, const uint8_t *addr);
bool btlist_has(const struct btlist *l, const uint8_t *addr);
bool btlist_has_kind(const struct btlist *l, enum device_kind kind);
/* The most recently connected entry of the kind, or NULL when none is listed. */
const struct btlist_entry *btlist_latest(const struct btlist *l, enum device_kind kind);
/* DEVICE_NO_KIND for an address not in the list. */
enum device_kind btlist_kind(const struct btlist *l, const uint8_t *addr);

/* secure tells whether the entry paired with LE Secure Connections. */
uint8_t btlist_pairing(const struct btlist_entry *e, bool secure);

/* connected[s] is the address of the device ready in slot s, or NULL; secure tells whether the
 * device at an address paired with LE Secure Connections. Returns the number of devices written. */
size_t btlist_devices(const struct btlist *l, const uint8_t *const connected[DEVICE_SLOTS],
		      bool (*secure)(const uint8_t addr[BTPOLICY_ADDR_LEN]),
		      struct diag_device out[BTPOLICY_STORED_MAX]);

#endif
```

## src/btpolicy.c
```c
#include <string.h>

#include "btpolicy.h"

enum device_kind btpolicy_kind_of(uint16_t appearance)
{
	switch (appearance) {
	case BTPOLICY_APPEARANCE_KEYBOARD:
		return DEVICE_KIND_KEYBOARD;
	case BTPOLICY_APPEARANCE_MOUSE:
		return DEVICE_KIND_MOUSE;
	default:
		return DEVICE_NO_KIND;
	}
}

void btpolicy_init(struct btpolicy *p)
{
	*p = (struct btpolicy){0};
}

static bool refused(const struct btpolicy *p, const uint8_t *addr)
{
	for (uint8_t i = 0; i < p->refused_count; i++) {
		if (memcmp(p->refused[i], addr, BTPOLICY_ADDR_LEN) == 0) {
			return true;
		}
	}
	return false;
}

static bool setting_up(const struct btpolicy *p)
{
	for (int k = 0; k < DEVICE_KINDS; k++) {
		if (p->slots[k].state == BTPOLICY_CONNECTING ||
		    p->slots[k].state == BTPOLICY_CONNECTED) {
			return true;
		}
	}
	return false;
}

bool btpolicy_interesting(const struct btpolicy_advert *a)
{
	return a->connectable && (a->stored || (a->hid_service && a->kind != DEVICE_NO_KIND));
}

enum btpolicy_want btpolicy_wants(const struct btpolicy *p, const struct btpolicy_advert *a,
				  bool window_open, uint8_t stored_count, uint32_t now_ms)
{
	const struct btpolicy_slot *s;

	if (!btpolicy_interesting(a) || a->kind == DEVICE_NO_KIND || setting_up(p)) {
		return BTPOLICY_IGNORE;
	}
	s = &p->slots[a->kind];
	if (s->dropping) {
		return BTPOLICY_IGNORE;
	}
	if (a->stored) {
		bool waited = !s->retry_pending || (int32_t)(now_ms - s->retry_at_ms) >= 0;

		return s->state == BTPOLICY_IDLE && !window_open && waited ? BTPOLICY_CONNECT
									    : BTPOLICY_IGNORE;
	}
	if (!window_open || a->directed || stored_count >= BTPOLICY_STORED_MAX ||
	    refused(p, a->addr)) {
		return BTPOLICY_IGNORE;
	}
	return s->state == BTPOLICY_IDLE ? BTPOLICY_CONNECT : BTPOLICY_REPLACE;
}

void btpolicy_connecting(struct btpolicy *p, const struct btpolicy_advert *a)
{
	struct btpolicy_slot *s = &p->slots[a->kind];

	s->state = BTPOLICY_CONNECTING;
	memcpy(s->peer, a->addr, BTPOLICY_ADDR_LEN);
	s->peer_stored = a->stored;
}

void btpolicy_dropping(struct btpolicy *p, enum device_kind kind)
{
	p->slots[kind].dropping = true;
}

void btpolicy_connected(struct btpolicy *p, enum device_kind kind)
{
	p->slots[kind].state = BTPOLICY_CONNECTED;
}

const uint8_t *btpolicy_peer(const struct btpolicy *p, enum device_kind kind)
{
	return p->slots[kind].state == BTPOLICY_IDLE ? NULL : p->slots[kind].peer;
}

static void refuse_peer(struct btpolicy *p, const uint8_t *peer)
{
	if (!refused(p, peer) && p->refused_count < BTPOLICY_STORED_MAX) {
		memcpy(p->refused[p->refused_count++], peer, BTPOLICY_ADDR_LEN);
	}
}

enum btpolicy_pairing btpolicy_paired(struct btpolicy *p, enum device_kind kind,
				      bool passkey_used)
{
	struct btpolicy_slot *s = &p->slots[kind];

	if (kind == DEVICE_KIND_KEYBOARD && p->window_open && p->passkey_demanded && !passkey_used) {
		refuse_peer(p, s->peer);
		return BTPOLICY_PAIRING_FORGOTTEN;
	}
	s->peer_stored = true;
	return BTPOLICY_PAIRING_KEPT;
}

void btpolicy_ready(struct btpolicy *p, enum device_kind kind)
{
	p->slots[kind].state = BTPOLICY_READY;
}

bool btpolicy_is_ready(const struct btpolicy *p, enum device_kind kind)
{
	return p->slots[kind].state == BTPOLICY_READY;
}

void btpolicy_disconnected(struct btpolicy *p, enum device_kind kind, uint32_t now_ms,
			   bool never_joined)
{
	struct btpolicy_slot *s = &p->slots[kind];
	bool failed = s->state != BTPOLICY_READY && s->peer_stored;
	bool quick = failed && never_joined && s->quick_retries < BTPOLICY_QUICK_RETRIES;

	s->quick_retries = quick ? s->quick_retries + 1 : 0;
	s->retry_pending = failed && !quick;
	s->retry_at_ms = now_ms + BTPOLICY_RETRY_MS;
	s->state = BTPOLICY_IDLE;
	s->dropping = false;
}

enum btpolicy_security btpolicy_security_failed(struct btpolicy *p, enum device_kind kind,
						enum btpolicy_failure why)
{
	struct btpolicy_slot *s = &p->slots[kind];

	if (s->peer_stored) {
		return why == BTPOLICY_FAILURE_KEY_MISSING ? BTPOLICY_BOND_LOST
							   : BTPOLICY_SECURITY_FAILED;
	}
	if (why != BTPOLICY_FAILURE_REFUSAL) {
		return BTPOLICY_SECURITY_FAILED;
	}
	if (refused(p, s->peer)) {
		return BTPOLICY_REFUSED_BEFORE;
	}
	refuse_peer(p, s->peer);
	return BTPOLICY_PAIRING_REFUSED;
}

void btpolicy_window(struct btpolicy *p, bool open, bool passkey_demanded)
{
	if (p->window_open && !open) {
		p->refused_count = 0;
	}
	p->window_open = open;
	p->passkey_demanded = open && passkey_demanded;
}

enum btpolicy_scan btpolicy_scan(const struct btpolicy *p)
{
	bool slot_free = false;

	if (setting_up(p)) {
		return BTPOLICY_SCAN_OFF;
	}
	if (p->window_open) {
		return BTPOLICY_SCAN_ACTIVE;
	}
	for (int k = 0; k < DEVICE_KINDS; k++) {
		slot_free |= p->slots[k].state == BTPOLICY_IDLE;
	}
	return slot_free ? BTPOLICY_SCAN_PASSIVE : BTPOLICY_SCAN_OFF;
}
```

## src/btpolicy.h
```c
#ifndef BTPOLICY_H
#define BTPOLICY_H

#include <stdbool.h>
#include <stdint.h>

#include "device.h"

#define BTPOLICY_STORED_MAX 8
#define BTPOLICY_RETRY_MS 1000
#define BTPOLICY_QUICK_RETRIES 3
/* The address type, then the six address bytes. */
#define BTPOLICY_ADDR_LEN 7
#define BTPOLICY_NAME_MAX 32
#define BTPOLICY_APPEARANCE_KEYBOARD 0x03c1
#define BTPOLICY_APPEARANCE_MOUSE 0x03c2

struct btpolicy_advert {
	uint8_t addr[BTPOLICY_ADDR_LEN];
	bool connectable;
	bool directed;
	bool hid_service;
	bool stored;
	/* From the appearance for a new device, from the stored list for a stored one. */
	enum device_kind kind;
	/* Empty unless the advert or its scan response named the device. */
	char name[BTPOLICY_NAME_MAX + 1];
};

enum btpolicy_state {
	BTPOLICY_IDLE,
	BTPOLICY_CONNECTING,
	BTPOLICY_CONNECTED,
	/* The device's report map is read and its reports are forwarded. */
	BTPOLICY_READY,
};

enum btpolicy_want {
	BTPOLICY_IGNORE,
	BTPOLICY_CONNECT,
	/* The slot's device is to be dropped first; the advert is wanted once the slot is idle. */
	BTPOLICY_REPLACE,
};

enum btpolicy_scan {
	BTPOLICY_SCAN_OFF,
	BTPOLICY_SCAN_PASSIVE,
	BTPOLICY_SCAN_ACTIVE,
};

enum btpolicy_failure {
	/* The device or the dongle turned the pairing down. */
	BTPOLICY_FAILURE_REFUSAL,
	/* The device no longer holds its side of the bond. */
	BTPOLICY_FAILURE_KEY_MISSING,
	/* The link dropped before security was settled. */
	BTPOLICY_FAILURE_LINK,
};

enum btpolicy_pairing {
	BTPOLICY_PAIRING_KEPT,
	BTPOLICY_PAIRING_FORGOTTEN,
};

enum btpolicy_security {
	BTPOLICY_PAIRING_REFUSED,
	/* The same device refused earlier in this window. */
	BTPOLICY_REFUSED_BEFORE,
	BTPOLICY_BOND_LOST,
	BTPOLICY_SECURITY_FAILED,
};

struct btpolicy_slot {
	enum btpolicy_state state;
	uint8_t peer[BTPOLICY_ADDR_LEN];
	bool peer_stored;
	bool dropping;
	bool retry_pending;
	uint8_t quick_retries;
	uint32_t retry_at_ms;
};

struct btpolicy {
	struct btpolicy_slot slots[DEVICE_KINDS];
	bool window_open;
	bool passkey_demanded;
	/* Devices that refused to pair in the open window. */
	uint8_t refused[BTPOLICY_STORED_MAX][BTPOLICY_ADDR_LEN];
	uint8_t refused_count;
};

enum device_kind btpolicy_kind_of(uint16_t appearance);
void btpolicy_init(struct btpolicy *p);
/* False for an advert no rule can want, whatever the state. */
bool btpolicy_interesting(const struct btpolicy_advert *a);
/* A stored device is not connected to while a pairing window is open, and only one device is set
 * up at a time. */
enum btpolicy_want btpolicy_wants(const struct btpolicy *p, const struct btpolicy_advert *a,
				  bool window_open, uint8_t stored_count, uint32_t now_ms);
void btpolicy_connecting(struct btpolicy *p, const struct btpolicy_advert *a);
void btpolicy_dropping(struct btpolicy *p, enum device_kind kind);
void btpolicy_connected(struct btpolicy *p, enum device_kind kind);
/* The device being connected to or connected in the slot, or NULL. */
const uint8_t *btpolicy_peer(const struct btpolicy *p, enum device_kind kind);
/* A keyboard that paired without the passkey its window demands is to be forgotten; it is not
 * wanted again until the window closes. A mouse is always kept. */
enum btpolicy_pairing btpolicy_paired(struct btpolicy *p, enum device_kind kind,
				      bool passkey_used);
void btpolicy_ready(struct btpolicy *p, enum device_kind kind);
bool btpolicy_is_ready(const struct btpolicy *p, enum device_kind kind);
/* A stored device whose connection ended before it was ready leaves its slot alone for
 * BTPOLICY_RETRY_MS, except for the first BTPOLICY_QUICK_RETRIES in a row that never joined the
 * connection. */
void btpolicy_disconnected(struct btpolicy *p, enum device_kind kind, uint32_t now_ms,
			   bool never_joined);
/* A device that refuses to pair is not wanted again until the window closes. */
enum btpolicy_security btpolicy_security_failed(struct btpolicy *p, enum device_kind kind,
						enum btpolicy_failure why);
/* Told the pairing window's state every tick; the refusals are forgotten when it closes. */
void btpolicy_window(struct btpolicy *p, bool open, bool passkey_demanded);
/* Active while a pairing window is open, since a new device may give its appearance only in its
 * scan response. */
enum btpolicy_scan btpolicy_scan(const struct btpolicy *p);

#endif
```

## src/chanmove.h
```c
#ifndef CHANMOVE_H
#define CHANMOVE_H

#define CHANMOVE_NO_HOME (-1)

enum chanmove_result {
	CHANMOVE_DONE,
	/* The keyboard never looks for the dongle on that channel. */
	CHANMOVE_NOT_A_CHANNEL,
	/* No keyboard paired, pairing open, in NuPhy the host suspended or, in Unifying, a pairing
	 * handshake running. */
	CHANMOVE_NOT_MOVABLE,
};

#endif
```

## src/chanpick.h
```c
#ifndef CHANPICK_H
#define CHANPICK_H

#include <stdbool.h>
#include <stdint.h>

#define CHAN_FIRST 2
#define CHAN_LAST 80
#define CHAN_COUNT (CHAN_LAST - CHAN_FIRST + 1)
#define CHAN_SAMPLES 32
#define CHAN_MIN_SPACING 10

static inline bool chan_in_range(int ch)
{
	return ch >= CHAN_FIRST && ch <= CHAN_LAST;
}

struct chan_survey {
	int8_t dbm[CHAN_COUNT][CHAN_SAMPLES];
};

/*
 * Writes the three quietest channels at least CHAN_MIN_SPACING apart, never a BLE advertising
 * channel, quietest first.
 */
void chan_pick(const struct chan_survey *s, uint8_t out[3]);

#endif
```
